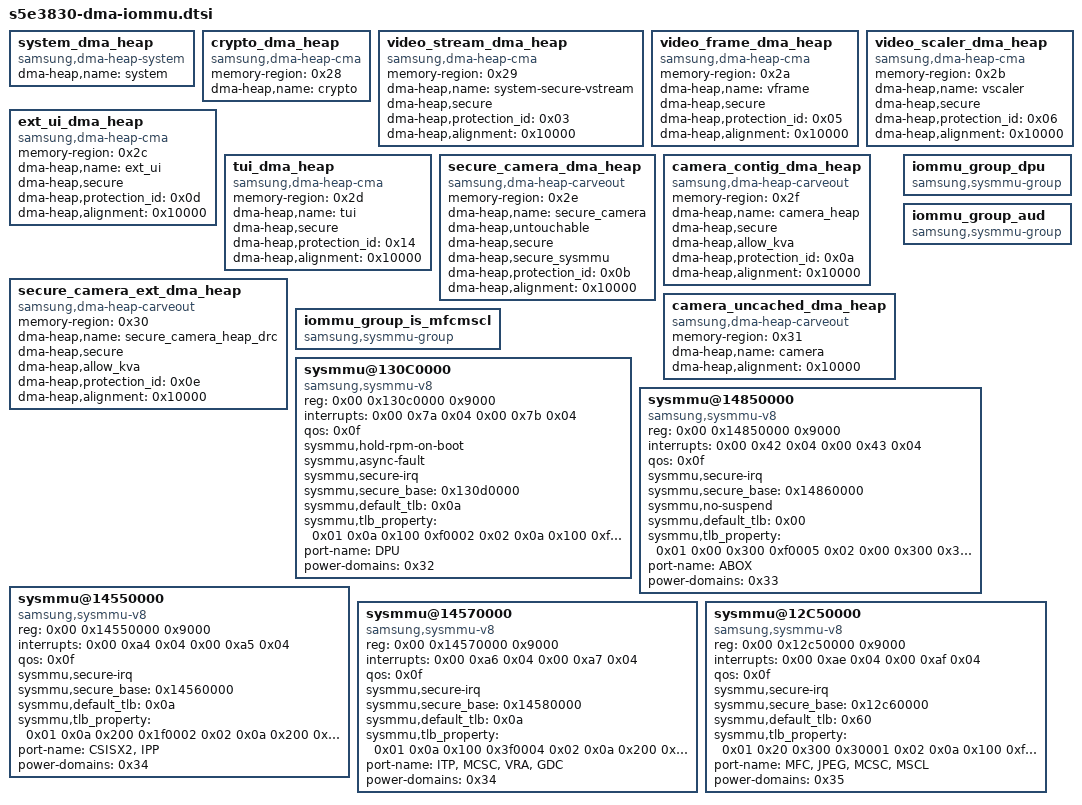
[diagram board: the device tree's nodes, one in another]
/* Samsung Exynos 850 (S5E3830) - DMA heap allocators and SYSMMU */

	system_dma_heap {
		compatible = "samsung,dma-heap-system";
		dma-heap,name = "system";
	};

	crypto_dma_heap {
		compatible = "samsung,dma-heap-cma";
		memory-region = <0x28>;
		dma-heap,name = "crypto";
	};

	video_stream_dma_heap {
		compatible = "samsung,dma-heap-cma";
		memory-region = <0x29>;
		dma-heap,name = "system-secure-vstream";
		dma-heap,secure;
		dma-heap,protection_id = <0x03>;
		dma-heap,alignment = <0x10000>;
	};

	video_frame_dma_heap {
		compatible = "samsung,dma-heap-cma";
		memory-region = <0x2a>;
		dma-heap,name = "vframe";
		dma-heap,secure;
		dma-heap,protection_id = <0x05>;
		dma-heap,alignment = <0x10000>;
	};

	video_scaler_dma_heap {
		compatible = "samsung,dma-heap-cma";
		memory-region = <0x2b>;
		dma-heap,name = "vscaler";
		dma-heap,secure;
		dma-heap,protection_id = <0x06>;
		dma-heap,alignment = <0x10000>;
	};

	ext_ui_dma_heap {
		compatible = "samsung,dma-heap-cma";
		memory-region = <0x2c>;
		dma-heap,name = "ext_ui";
		dma-heap,secure;
		dma-heap,protection_id = <0x0d>;
		dma-heap,alignment = <0x10000>;
	};

	tui_dma_heap {
		compatible = "samsung,dma-heap-cma";
		memory-region = <0x2d>;
		dma-heap,name = "tui";
		dma-heap,secure;
		dma-heap,protection_id = <0x14>;
		dma-heap,alignment = <0x10000>;
	};

	secure_camera_dma_heap {
		compatible = "samsung,dma-heap-carveout";
		memory-region = <0x2e>;
		dma-heap,name = "secure_camera";
		dma-heap,untouchable;
		dma-heap,secure;
		dma-heap,secure_sysmmu;
		dma-heap,protection_id = <0x0b>;
		dma-heap,alignment = <0x10000>;
	};

	camera_contig_dma_heap {
		compatible = "samsung,dma-heap-carveout";
		memory-region = <0x2f>;
		dma-heap,name = "camera_heap";
		dma-heap,secure;
		dma-heap,allow_kva;
		dma-heap,protection_id = <0x0a>;
		dma-heap,alignment = <0x10000>;
	};

	secure_camera_ext_dma_heap {
		compatible = "samsung,dma-heap-carveout";
		memory-region = <0x30>;
		dma-heap,name = "secure_camera_heap_drc";
		dma-heap,secure;
		dma-heap,allow_kva;
		dma-heap,protection_id = <0x0e>;
		dma-heap,alignment = <0x10000>;
	};

	camera_uncached_dma_heap {
		compatible = "samsung,dma-heap-carveout";
		memory-region = <0x31>;
		dma-heap,name = "camera";
		dma-heap,alignment = <0x10000>;
	};

	iommu_group_dpu {
		compatible = "samsung,sysmmu-group";
		phandle = <0x70>;
	};

	iommu_group_aud {
		compatible = "samsung,sysmmu-group";
		phandle = <0x7a>;
	};

	iommu_group_is_mfcmscl {
		compatible = "samsung,sysmmu-group";
		phandle = <0x8b>;
	};

	sysmmu@130C0000 {
		compatible = "samsung,sysmmu-v8";
		reg = <0x00 0x130c0000 0x9000>;
		interrupts = <0x00 0x7a 0x04 0x00 0x7b 0x04>;
		qos = <0x0f>;
		sysmmu,hold-rpm-on-boot;
		sysmmu,async-fault;
		sysmmu,secure-irq;
		sysmmu,secure_base = <0x130d0000>;
		sysmmu,default_tlb = <0x0a>;
		sysmmu,tlb_property = <0x01 0x0a 0x100 0xf0002 0x02 0x0a 0x100 0xf0004 0x03 0x0a 0x100 0xf0006 0x04 0x0a 0x100 0xf0008>;
		port-name = "DPU";
		#iommu-cells = <0x00>;
		power-domains = <0x32>;
		phandle = <0x6f>;
	};

	sysmmu@14850000 {
		compatible = "samsung,sysmmu-v8";
		reg = <0x00 0x14850000 0x9000>;
		interrupts = <0x00 0x42 0x04 0x00 0x43 0x04>;
		qos = <0x0f>;
		sysmmu,secure-irq;
		sysmmu,secure_base = <0x14860000>;
		sysmmu,no-suspend;
		sysmmu,default_tlb = <0x00>;
		sysmmu,tlb_property = <0x01 0x00 0x300 0xf0005 0x02 0x00 0x300 0x30000 0x03 0x00 0x100 0x30003>;
		port-name = "ABOX";
		#iommu-cells = <0x00>;
		power-domains = <0x33>;
		phandle = <0x78>;
	};

	sysmmu@14550000 {
		compatible = "samsung,sysmmu-v8";
		reg = <0x00 0x14550000 0x9000>;
		interrupts = <0x00 0xa4 0x04 0x00 0xa5 0x04>;
		qos = <0x0f>;
		sysmmu,secure-irq;
		sysmmu,secure_base = <0x14560000>;
		sysmmu,default_tlb = <0x0a>;
		sysmmu,tlb_property = <0x01 0x0a 0x200 0x1f0002 0x02 0x0a 0x200 0x1f0004 0x03 0x0a 0x200 0x1f0006 0x04 0x0a 0x200 0x1f0008 0x05 0x0a 0x200 0x1f000a 0x06 0x0a 0x200 0x1f000c 0x07 0x0a 0x200 0x1f000e 0x08 0x0a 0x100 0x1f0001 0x09 0x0a 0x100 0x1f0011 0x0a 0x0a 0x200 0x1f0001 0x0b 0x0a 0x200 0x1f0003 0x0c 0x0a 0x200 0x1f0005 0x0d 0x0a 0x200 0x1f0007 0x0e 0x0a 0x200 0x1f0009 0x0f 0x0a 0x200 0x1f0011 0x10 0x0a 0x200 0x1f0013 0x11 0x0a 0x200 0x1f0015 0x12 0x0a 0x200 0x1f0017 0x13 0x0a 0x200 0x1f0019>;
		port-name = "CSISX2, IPP";
		#iommu-cells = <0x00>;
		power-domains = <0x34>;
		phandle = <0x8d>;
	};

	sysmmu@14570000 {
		compatible = "samsung,sysmmu-v8";
		reg = <0x00 0x14570000 0x9000>;
		interrupts = <0x00 0xa6 0x04 0x00 0xa7 0x04>;
		qos = <0x0f>;
		sysmmu,secure-irq;
		sysmmu,secure_base = <0x14580000>;
		sysmmu,default_tlb = <0x0a>;
		sysmmu,tlb_property = <0x01 0x0a 0x100 0x3f0004 0x02 0x0a 0x200 0x3f0004 0x03 0x0a 0x200 0x3f0001 0x04 0x0a 0x200 0x3f0005 0x05 0x0a 0x200 0x3f0009 0x06 0x0a 0x300 0x30003 0x07 0x4a 0x200 0x30002 0x08 0x0a 0x200 0x30002>;
		port-name = "ITP, MCSC, VRA, GDC";
		#iommu-cells = <0x00>;
		power-domains = <0x34>;
		phandle = <0x8e>;
	};

	sysmmu@12C50000 {
		compatible = "samsung,sysmmu-v8";
		reg = <0x00 0x12c50000 0x9000>;
		interrupts = <0x00 0xae 0x04 0x00 0xaf 0x04>;
		qos = <0x0f>;
		sysmmu,secure-irq;
		sysmmu,secure_base = <0x12c60000>;
		sysmmu,default_tlb = <0x60>;
		sysmmu,tlb_property = <0x01 0x20 0x300 0x30001 0x02 0x0a 0x100 0xf0002 0x03 0x0a 0x100 0xf0006 0x04 0x0a 0x100 0xf000a 0x05 0x0a 0x200 0xf0002 0x06 0x0a 0x200 0xf0006 0x07 0x0a 0x200 0xf000a 0x08 0xaa 0x100 0x3f0003 0x09 0xaa 0x100 0x3f0007 0x0a 0x4a 0x100 0x3f000b 0x0b 0x4a 0x100 0x3f000f 0x0c 0xaa 0x200 0x3f0023 0x0d 0x4a 0x200 0x3f0027 0x0e 0x4a 0x200 0x3f002b>;
		port-name = "MFC, JPEG, MCSC, MSCL";
		#iommu-cells = <0x00>;
		power-domains = <0x35>;
		phandle = <0x8a>;
	};
